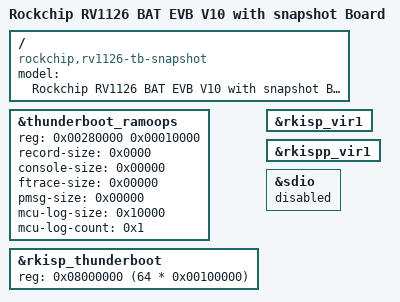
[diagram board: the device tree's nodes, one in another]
// SPDX-License-Identifier: (GPL-2.0+ OR MIT)
/*
 * Copyright (c) 2021 Rockchip Electronics Co., Ltd.
 */

/dts-v1/;
#include "rv1126-bat-evb-v10.dtsi"

/ {
	model = "Rockchip RV1126 BAT EVB V10 with snapshot Board";
	compatible = "rockchip,rv1126-tb-snapshot", "rockchip,rv1126";
};

&thunderboot_ramoops {
	reg = <0x00280000 0x00010000>;
	record-size = <0x0000>;
	console-size = <0x00000>;
	ftrace-size = <0x00000>;
	pmsg-size = <0x00000>;
	mcu-log-size = <0x10000>;
	mcu-log-count = <0x1>;
};

&rkisp_thunderboot {
	reg = <0x08000000 (64 * 0x00100000)>;
};

&rkisp_vir1 {
	status = "okay";
};

&rkispp_vir1 {
	status = "okay";
};

&sdio {
	status = "disabled";
};
